VERSION "created by canmatrix"

NS_ :

BS_:

BU_: Jetson RT SYS MTR DCDC

BO_ 1 SAFETY_ESTOP: 0 RT

BO_ 17 SYS_SAFETY_STS: 2 SYS
 SG_ SYS_EstopActive : 7|8@0+ (1,0) [0|1] "" RT,Jetson
 SG_ SYS_HeartbeatOk : 15|8@0+ (1,0) [0|1] "" RT,Jetson

BO_ 18 SYS_DCDC_CMD: 1 SYS
 SG_ SYS_DcdcEnable : 7|8@0+ (1,0) [0|1] "" DCDC

BO_ 272 SYS_MODE_CMD: 1 SYS
 SG_ SYS_Mode : 7|8@0+ (1,0) [0|2] "enum" RT

BO_ 288 SYS_THROTTLE_STS: 2 MTR
 SG_ SYS_ThrottleSpeed : 7|16@0- (1,0) [-500|3000] "mm/s" RT,Jetson

BO_ 516 RT_DRIVE_CMD: 5 RT
 SG_ RT_MotorSpeed : 7|32@0- (1,0) [-500|3000] "mm/s" SYS,MTR
 SG_ RT_Gear : 39|8@0+ (1,0) [0|3] "enum" SYS,MTR

BO_ 517 RT_BRAKE_CMD: 4 RT
 SG_ RT_BrakePressure : 7|32@0- (1,0) [0|20000] "kPa" SYS

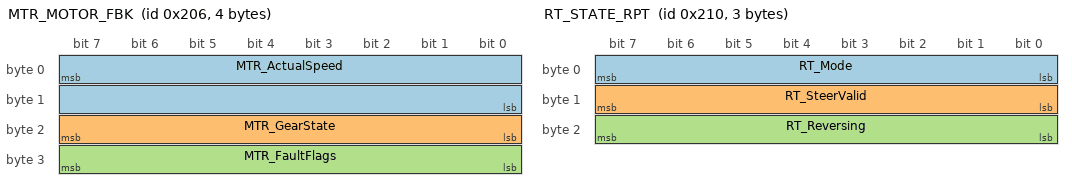
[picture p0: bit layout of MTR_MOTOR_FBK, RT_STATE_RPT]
BO_ 518 MTR_MOTOR_FBK: 4 MTR
 SG_ MTR_ActualSpeed : 7|16@0- (1,0) [-500|3000] "mm/s" RT,SYS
 SG_ MTR_GearState : 23|8@0+ (1,0) [0|3] "enum" RT,SYS
 SG_ MTR_FaultFlags : 31|8@0+ (1,0) [0|255] "" RT,SYS

BO_ 528 RT_STATE_RPT: 3 RT
 SG_ RT_Mode : 7|8@0+ (1,0) [0|2] "enum" Jetson
 SG_ RT_SteerValid : 15|8@0+ (1,0) [0|1] "" Jetson
 SG_ RT_Reversing : 23|8@0+ (1,0) [0|1] "" Jetson

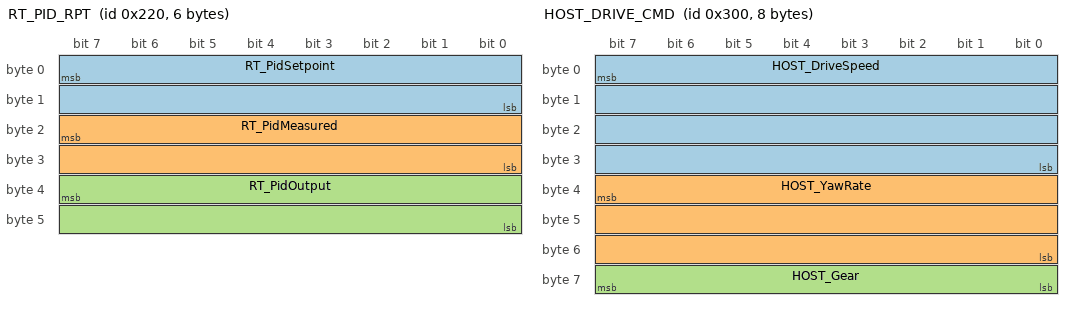
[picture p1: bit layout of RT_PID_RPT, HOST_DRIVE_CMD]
BO_ 544 RT_PID_RPT: 6 RT
 SG_ RT_PidSetpoint : 7|16@0- (1,0) [-32768|32767] "mm/s" Jetson
 SG_ RT_PidMeasured : 23|16@0- (1,0) [-32768|32767] "mm/s" Jetson
 SG_ RT_PidOutput : 39|16@0- (1,0) [-32768|32767] "" Jetson

BO_ 768 HOST_DRIVE_CMD: 8 Jetson
 SG_ HOST_DriveSpeed : 7|32@0- (1,0) [-500|3000] "mm/s" RT
 SG_ HOST_YawRate : 39|24@0- (1,0) [-3000|3000] "mrad/s" RT
 SG_ HOST_Gear : 63|8@0+ (1,0) [0|3] "enum" RT

BO_ 769 HOST_BRAKE_REQ: 4 Jetson
 SG_ HOST_BrakePressure : 7|32@0- (1,0) [0|20000] "kPa" RT

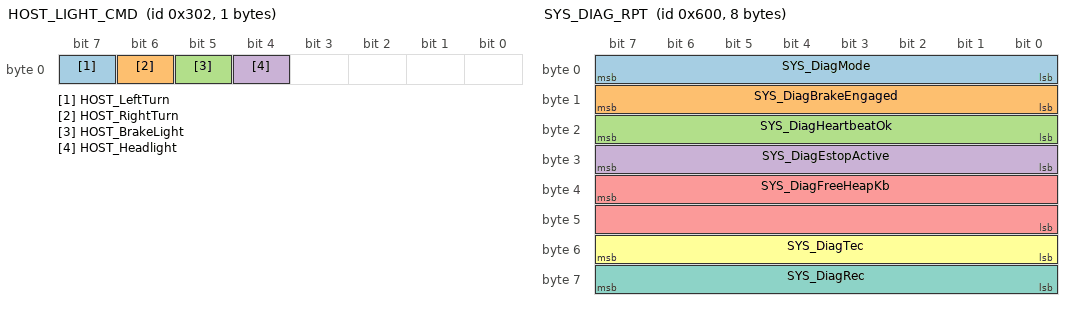
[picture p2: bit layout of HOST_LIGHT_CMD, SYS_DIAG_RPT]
BO_ 770 HOST_LIGHT_CMD: 1 Jetson
 SG_ HOST_LeftTurn : 7|1@0+ (1,0) [0|1] "" RT,SYS
 SG_ HOST_RightTurn : 6|1@0+ (1,0) [0|1] "" RT,SYS
 SG_ HOST_BrakeLight : 5|1@0+ (1,0) [0|1] "" RT,SYS
 SG_ HOST_Headlight : 4|1@0+ (1,0) [0|1] "" RT,SYS

BO_ 1024 RT_OBSTACLE_RPT: 4 RT
 SG_ RT_ObstacleDistance : 7|32@0+ (1,0) [0|4294967295] "mm" Jetson

BO_ 1536 SYS_DIAG_RPT: 8 SYS
 SG_ SYS_DiagMode : 7|8@0+ (1,0) [0|2] "" RT,Jetson
 SG_ SYS_DiagBrakeEngaged : 15|8@0+ (1,0) [0|1] "" RT,Jetson
 SG_ SYS_DiagHeartbeatOk : 23|8@0+ (1,0) [0|1] "" RT,Jetson
 SG_ SYS_DiagEstopActive : 31|8@0+ (1,0) [0|1] "" RT,Jetson
 SG_ SYS_DiagFreeHeapKb : 39|16@0+ (1,0) [0|65535] "KB" RT,Jetson
 SG_ SYS_DiagTec : 55|8@0+ (1,0) [0|255] "" RT,Jetson
 SG_ SYS_DiagRec : 63|8@0+ (1,0) [0|255] "" RT,Jetson

BO_ 2044 JETSON_HEARTBEAT: 1 Jetson
 SG_ Jetson_AliveCtr : 7|8@0+ (1,0) [0|255] "" RT

BO_ 2045 RT_HEARTBEAT: 1 RT
 SG_ RT_AliveCtr : 7|8@0+ (1,0) [0|255] "" Jetson,SYS

BO_ 2046 SYS_HEARTBEAT: 1 SYS
 SG_ SYS_AliveCtr : 7|8@0+ (1,0) [0|255] "" RT

CM_ BO_ 1  "DLC=0  the frame ID itself is the ESTOP signal. Bridged bidirectionally by RT. Highest priority CAN frame.";
CM_ BO_ 17  "Forwarded low->high by RT. Same payload on both buses.";
CM_ BO_ 18  "DC-DC converter control. Low bus only.";
CM_ BO_ 272  "0=Manual, 1=Auto, 2=ESTOP. Low bus only.";
CM_ BO_ 288  "Current vehicle speed from MTR STM32. Forwarded low->high by RT.";
CM_ BO_ 516  "MTR receives for motor actuation. SYS receives for EGAS L2 monitoring. ID 0x204 avoids collision with EPS-C 0x202.";
CM_ BO_ 517  "RT max-select: max(rt_obstacle, jetson_0x301) -> SYS SEB cmd.";
CM_ BO_ 518  "Motor feedback from STM32. Low bus only.";
CM_ BO_ 528  "RT state report to Jetson. High bus only.";
CM_ BO_ 544  "RESERVED, inactive. PID telemetry for Jetson debugging.";
CM_ BO_ 768  "Jetson Autoware.Auto drive command -> RT. High bus only.";
CM_ BO_ 769  "On demand. RT arbitrates: max(RT_computed, HOST_request) -> 0x205.";
CM_ BO_ 770  "Forwarded transparently high->low by RT.";
CM_ BO_ 1024  "RT reports min obstacle distance to Jetson at 10 Hz. High bus only.";
CM_ BO_ 1536  "SYS diagnostics report. Forwarded low->high by RT.";
CM_ BO_ 2044  "Not bridged, high bus only. Loss triggers controlled stop, not ESTOP.";
CM_ BO_ 2045  "RT sends independently on both buses (per-bus, NOT bridged). Separate counters.";
CM_ BO_ 2046  "Low bus only, never leaves low bus.";

CM_ SG_ 17 SYS_HeartbeatOk "0=RT alive counter frozen >1000ms, 1=incrementing";
CM_ SG_ 18 SYS_DcdcEnable "ESTOP->1(on); maintains 12V for MCUs, CAN transceivers, brake light";
CM_ SG_ 518 MTR_FaultFlags "bit0=ESTOP, bit1=CMD timeout, bit2=ADC fault, bit3=gear conflict";
CM_ SG_ 768 HOST_DriveSpeed "ROS 2: linear.x * 1000";
CM_ SG_ 768 HOST_YawRate "ROS 2: angular.z * 1000";
CM_ SG_ 1024 RT_ObstacleDistance "UINT32_MAX = no reading / timeout";
CM_ SG_ 2044 Jetson_AliveCtr "Timeout 1500ms -> controlled stop. Jetson is QM, not safety-critical.";
CM_ SG_ 2045 RT_AliveCtr "Low bus timeout 1000ms->SYS ESTOP; High bus 1500ms->Jetson stops /cmd_vel";
CM_ SG_ 2046 SYS_AliveCtr "10 Hz / 200ms timeout -> RT brake takeover + ESTOP";

CM_ BU_ Jetson "Orin NX, Linux + ROS 2, perception/planning";
CM_ BU_ RT "ESP32-S3, FreeRTOS, realtime kinematics + CAN gateway";
CM_ BU_ SYS "ESP32-S3, FreeRTOS, safety + motor + body control";
CM_ BU_ MTR "STM32, bare metal, motor DAC + gear relays (EGAS L1)";
CM_ BU_ DCDC "DC-DC converter (72V->12V), CAN 0x012 control";

BA_DEF_ BO_ "GenMsgCycleTime" INT 0 65535;

BA_ "GenMsgCycleTime" BO_ 17 200;
BA_ "GenMsgCycleTime" BO_ 18 100;
BA_ "GenMsgCycleTime" BO_ 288 10;
BA_ "GenMsgCycleTime" BO_ 516 10;
BA_ "GenMsgCycleTime" BO_ 517 20;
BA_ "GenMsgCycleTime" BO_ 518 20;
BA_ "GenMsgCycleTime" BO_ 528 100;
BA_ "GenMsgCycleTime" BO_ 544 100;
BA_ "GenMsgCycleTime" BO_ 768 10;
BA_ "GenMsgCycleTime" BO_ 1024 100;
BA_ "GenMsgCycleTime" BO_ 1536 1000;
BA_ "GenMsgCycleTime" BO_ 2044 500;
BA_ "GenMsgCycleTime" BO_ 2045 500;
BA_ "GenMsgCycleTime" BO_ 2046 100;

VAL_ 272 SYS_Mode 0 "Manual" 1 "Auto" 2 "ESTOP";
VAL_ 516 RT_Gear 0 "N" 1 "D" 2 "S" 3 "R";
VAL_ 518 MTR_GearState 0 "N" 1 "D" 2 "S" 3 "R";
VAL_ 518 MTR_FaultFlags 1 "Overcurrent" 2 "Overtemp" 4 "CommsLoss";
VAL_ 528 RT_Mode 0 "Manual" 1 "Auto" 2 "ESTOP";
VAL_ 768 HOST_Gear 0 "N" 1 "D" 2 "S" 3 "R";
